# VPAC0_PAR_VPAC_VISS0_S_VBUSP_VISS_NSF4V_CFG_MMR_VBUSP_NSF4VCORE register map
Vendor: Texas Instruments
Peripheral module from a debugger description file (folder J7ES).
Registers are 32-bit, read-write, reset 0x0 unless marked. A register's access mark holds for its fields unless they carry their own. Offsets are as the file gives them; lines under a group give offsets from that group; [hi:lo] are bit positions; {n}, {i} and the like mark numbered series; 'fields as' and 'values as' point back to an identical list; <NAME> marks a mode.

## VPAC0_PAR_VPAC_VISS0_S_VBUSP_VISS_NSF4V_CFG_MMR_VBUSP_NSF4VCORE
0x04 VISS_NSF4V_DBG — Diagnostic Register Control
  [5:0] RAM_MUX_CFG — Diagnostic Rd Wr access to Embedded RAM Selector Mux.
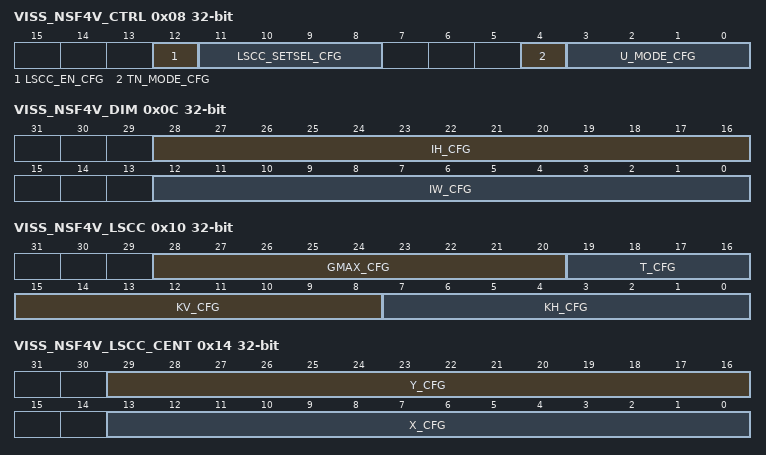
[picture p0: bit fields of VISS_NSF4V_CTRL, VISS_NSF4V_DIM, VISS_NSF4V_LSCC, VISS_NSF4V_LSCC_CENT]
0x08 VISS_NSF4V_CTRL — All modes are set here
  [12] LSCC_EN_CFG — enable Lens Shading Correction Compensation.
  [11:8] LSCC_SETSEL_CFG — bit per BAYER color component indicating which of two sets of 16 segment PWL Curve to use for
  [4] TN_MODE_CFG — single bit controlling T_n calculation
  [3:0] U_MODE_CFG — bit per BAYER color component indicating Decomp sub component
0x0C VISS_NSF4V_DIM — Input Output Frame dimensions in units of pixels. Same value for input and output
  [28:16] IH_CFG — (U13) input height in units of pixels minus 1.
  [12:0] IW_CFG — (U13) input width in units of pixels minus 1.
0x10 VISS_NSF4V_LSCC — Lens Shading Correction Compensation. First control register
  [28:20] GMAX_CFG — (U4.5)
  [19:16] T_CFG — (U4)
  [15:8] KV_CFG — (U2.6)
  [7:0] KH_CFG — (U2.6)
0x14 VISS_NSF4V_LSCC_CENT — Lens Shading Correction Compensation. Programmable Center of frame
  [29:16] Y_CFG — (S14) Vertical (Y) position of lens center
  [13:0] X_CFG — (S14) Horizontal (X) position of lens center
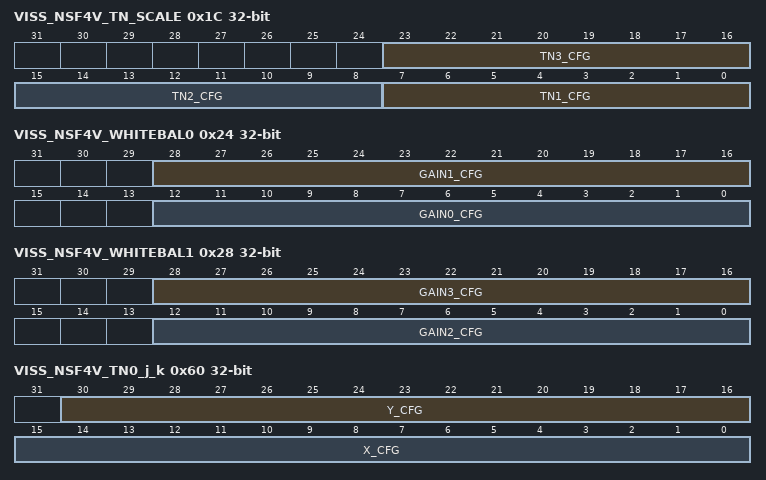
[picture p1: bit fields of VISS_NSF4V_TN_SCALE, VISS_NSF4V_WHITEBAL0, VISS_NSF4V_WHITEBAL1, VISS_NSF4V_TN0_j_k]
0x1C VISS_NSF4V_TN_SCALE — Tn scaling factor multiplied by all 4 color components Tn after 12 segment PWL. Different scaling factor per level
  [23:16] TN3_CFG — (U3.5) Level3.
  [15:8] TN2_CFG — (U3.5) Level2.
  [7:0] TN1_CFG — (U3.5) Level1.
0x20 VISS_NSF4V_U_KNEE — U suppression curve knee. Same knee value for all 9 levels x 4 color components.
  [5:0] U_KNEE_CFG — (U0.6) U Suppress curve knee.
0x24 VISS_NSF4V_WHITEBAL0 — White Balance Gain (Part0). Separate Gain for each of 4 colors
  [28:16] GAIN1_CFG — (U4.9) Gain for color 1
  [12:0] GAIN0_CFG — (U4.9) Gain for color 0
0x28 VISS_NSF4V_WHITEBAL1 — White Balance Gain (Part1). Separate Gain for each of 4 colors
  [28:16] GAIN3_CFG — (U4.9) Gain for color 3
  [12:0] GAIN2_CFG — (U4.9) Gain for color 2
0x60 VISS_NSF4V_TN0_j_k — T_n 12 segment piecewise linear curve Part0 (4 color x 12 segment) Offset = 000C0060h + (j * 60h) + (k * 8h); where j = 0h to 3h, k = 0h to Bh
  [30:16] Y_CFG — (U15) Y (U) value.
  [15:0] X_CFG — (U16) X (LL2) value.
0x64 VISS_NSF4V_TN1_j_k — T_n 12 segment piecewise linear curve Part1 (4 color x 12 segment) Offset = 000C0064h + (j * 60h) + (k * 8h); where j = 0h to 3h, k = 0h to Bh
  [15:0] S_CFG — (S5.11) S value.
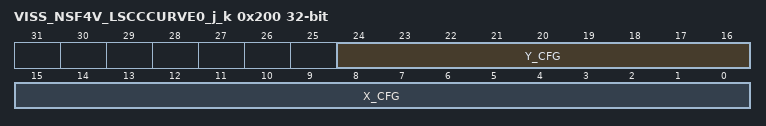
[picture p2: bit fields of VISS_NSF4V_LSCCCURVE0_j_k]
0x200 VISS_NSF4V_LSCCCURVE0_j_k — 16 segment piecewise linear curve Part0 (2 set x 16 segment) Offset = 000C0200h + (j * 80h) + (k * 8h); where j = 0h to 1h, k = 0h to Fh
  [24:16] Y_CFG — (U15.0) Y (U) value.
  [15:0] X_CFG — (U16) X (normalized radius from center) value.
0x204 VISS_NSF4V_LSCCCURVE1_j_k access per field — 16 segment piecewise linear curve Part1 (2 set x 16 segment) Offset = 000C0204h + (j * 80h) + (k * 8h); where j = 0h to 1h, k = 0h to Fh
  [15:0] S_CFG rw — (S5.11) S value.
